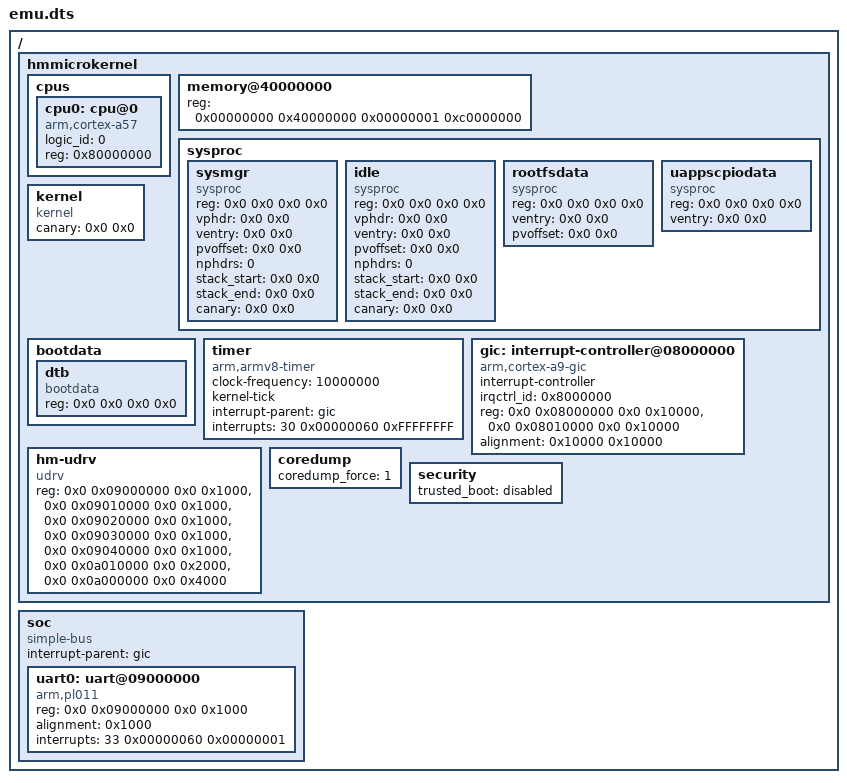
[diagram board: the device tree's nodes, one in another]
/dts-v1/;
/ { #address-cells = <2>; #size-cells = <2>; hmmicrokernel {
	#address-cells = <2>;
	#size-cells = <2>;

	cpus {
		#address-cells = <1>;
		#size-cells = <0>;
		cpu0: cpu@0 {
			compatible = "arm,cortex-a57", "arm,armv8";
			device_type = "cpu";
			logic_id = <0>;
			reg = <0x80000000>;

		};
	};

	memory@40000000 {
		device_type = "memory";
		reg = <0x00000000 0x40000000 0x00000001 0xc0000000>;
	};

	sysproc {
		#address-cells = <2>;
		#size-cells = <2>;
		sysmgr {
			compatible = "sysproc", "sysmgr";
			/* filled by bootloader */
			reg      = <0x0 0x0 0x0 0x0>;
			vphdr    = <0x0 0x0>;
			ventry   = <0x0 0x0>;
			pvoffset = <0x0 0x0>;
			nphdrs   = <0>;
			stack_start = <0x0 0x0>;
			stack_end = <0x0 0x0>;
			canary = <0x0 0x0>;
		};
		idle {
			compatible = "sysproc", "idle";
			/* filled by bootloader */
			reg      = <0x0 0x0 0x0 0x0>;
			vphdr    = <0x0 0x0>;
			ventry   = <0x0 0x0>;
			pvoffset = <0x0 0x0>;
			nphdrs   = <0>;
			stack_start = <0x0 0x0>;
			stack_end = <0x0 0x0>;
			canary = <0x0 0x0>;
		};
		rootfsdata {
			compatible = "sysproc", "rootfs";
			/* filled by bootloader */
			reg      = <0x0 0x0 0x0 0x0>;
			ventry   = <0x0 0x0>;
			pvoffset = <0x0 0x0>;
		};
		uappscpiodata {
			compatible = "sysproc", "uappscpio";
			/* filled by bootloader */
			reg      = <0x0 0x0 0x0 0x0>;
			ventry   = <0x0 0x0>;
		};
	};

	kernel {
		compatible = "kernel";
		/* filled by bootloader */
		canary = <0x0 0x0>;
	};

	bootdata {
		#address-cells = <2>;
		#size-cells = <2>;
		dtb {
			compatible = "bootdata", "dtb";
			/* filled by bootloader */
			reg = <0x0 0x0 0x0 0x0>;
		};
	};

	timer {
		compatible = "arm,armv8-timer";
		clock-frequency = <10000000>;
		kernel-tick;
		/* interrupt settings */
		interrupt-parent = <&gic>;

		/* PPI 30: Non-secure physical timer
		 * level triggered, hwprio:0x60 */
		interrupts = <30 0x00000060 0xFFFFFFFF>;
	};

	/* See Documentation/dts-gic.md for interrupts and distributor_config */
	gic: interrupt-controller@08000000 {
		compatible = "arm,cortex-a9-gic";
		#interrupt-cells = <3>;
		interrupt-controller;
		irqctrl_id = <0x8000000>;
		/* Controller address has 0x100 offset, handle this in driver */
		reg =   <0x0 0x08000000 0x0 0x10000>,	/* GICD */
			<0x0 0x08010000 0x0 0x10000>;	/* GICR */
		alignment = <0x10000 0x10000>;
	};

	hm-udrv {
		compatible = "udrv";
		reg = <0x0 0x09000000 0x0 0x1000>,
		      <0x0 0x09010000 0x0 0x1000>,
		      <0x0 0x09020000 0x0 0x1000>,
		      <0x0 0x09030000 0x0 0x1000>,
		      <0x0 0x09040000 0x0 0x1000>,
		      <0x0 0x0a010000 0x0 0x2000>,
		      <0x0 0x0a000000 0x0 0x4000>;
	};

	coredump {
		coredump_force = <1>;
	};

	security {
		trusted_boot = "disabled";
	};
	};

	soc {
		compatible = "simple-bus";
		#address-cells = <2>;
		#size-cells = <2>;
		ranges;
		interrupt-parent = <&gic>;

		uart0: uart@09000000 {
			compatible = "arm,pl011","arm,pl011,uart";
			reg = <0x0 0x09000000 0x0 0x1000>;
			alignment = <0x1000>;
			interrupts = <33 0x00000060 0x00000001>;
		};
	};
};
